# RP2350 register map
Vendor: Raspberry Pi; Series: RP; File version: 0.1
CPU: CM33 r1p0, little endian, MPU, FPU, DSP, VTOR, 4 interrupt priority bits, 52 interrupts, 8 SAU regions
Registers are 32-bit, read-write, reset 0x0 unless marked. A register's access mark holds for its fields unless they carry their own. Offsets are from the block's base; [hi:lo] are bit positions.

## HSTX_FIFO — FIFO status and write access for HSTX
Base 0x50600000
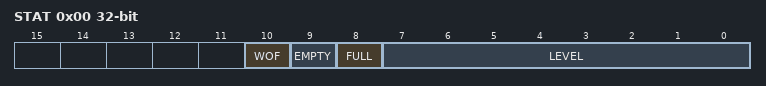
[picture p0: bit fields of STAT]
0x00 STAT — FIFO status
  [10] WOF write-1-clears — FIFO was written when full. Write 1 to clear.
  [9] EMPTY ro — Pre-defined description
  [8] FULL ro — Pre-defined description
  [7:0] LEVEL ro — Pre-defined description
0x04 FIFO — Write access to FIFO
  [31:0] FIFO wo — Pre-defined description

## EPPB — Cortex-M33 EPPB vendor register block for RP2350
Base 0xE0080000
0x00 NMI_MASK0 — NMI mask for IRQs 0 through 31. This register is core-local, and is reset by a processor warm reset.
  [31:0] NMI_MASK0 — Pre-defined description
0x04 NMI_MASK1 — NMI mask for IRQs 0 though 51. This register is core-local, and is reset by a processor warm reset.
  [19:0] NMI_MASK1 — Pre-defined description
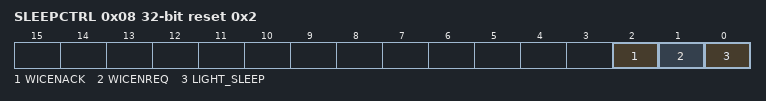
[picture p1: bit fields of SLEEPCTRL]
0x08 SLEEPCTRL reset 0x2 — Nonstandard sleep control register
  [2] WICENACK ro — Status signal from the processor's interrupt controller. Changes to WICENREQ are eventually reflected in WICENACK.
  [1] WICENREQ — Request that the next processor deep sleep is a WIC sleep. After setting this bit, before sleeping, poll WICENACK to ensure the processor interrupt controller has acknowledged the change.
  [0] LIGHT_SLEEP — By default, any processor sleep will deassert the system-level clock request. Reenabling the clocks incurs 5 cycles of additional latency on wakeup. Setting LIGHT_SLEEP to 1 keeps the clock request asserted during a normal sleep (Arm SCR.SLEEPDEEP = 0), for faster wakeup. Processor deep sleep (Arm SCR.SLEEPDEEP = 1) is not affected, and will always deassert the system-level clock request.

## XIP_AUX — Auxiliary DMA access to XIP FIFOs, via fast AHB bus access
Base 0x50500000
0x00 STREAM — Read the XIP stream FIFO (fast bus access to XIP_CTRL_STREAM_FIFO)
  [31:0] STREAM ro read-modifies — Pre-defined description
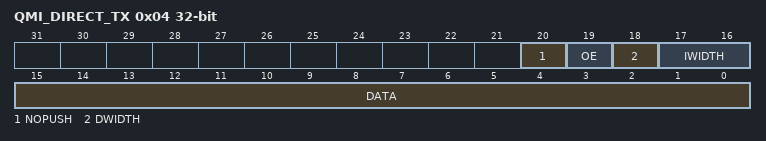
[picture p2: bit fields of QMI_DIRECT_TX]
0x04 QMI_DIRECT_TX — Write to the QMI direct-mode TX FIFO (fast bus access to QMI_DIRECT_TX)
  [20] NOPUSH wo — Inhibit the RX FIFO push that would correspond to this TX FIFO entry. Useful to avoid garbage appearing in the RX FIFO when pushing the command at the beginning of a SPI transfer.
  [19] OE wo — Output enable (active-high). For single width (SPI), this field is ignored, and SD0 is always set to output, with SD1 always set to input. For dual and quad width (DSPI/QSPI), this sets whether the relevant SDx pads are set to output whilst transferring this FIFO record. In this case the command/address should have OE set, and the data transfer should have OE set or clear depending on the direction of the transfer.
  [18] DWIDTH wo — Data width. If 0, hardware will transmit the 8 LSBs of the DIRECT_TX DATA field, and return an 8-bit value in the 8 LSBs of DIRECT_RX. If 1, the full 16-bit width is used. 8-bit and 16-bit transfers can be mixed freely.
  [17:16] IWIDTH wo — Configure whether this FIFO record is transferred with single/dual/quad interface width (0/1/2). Different widths can be mixed freely.
    0=S (Single width); 1=D (Dual width); 2=Q (Quad width)
  [15:0] DATA wo — Data pushed here will be clocked out falling edges of SCK (or before the very first rising edge of SCK, if this is the first pulse). For each byte clocked out, the interface will simultaneously sample one byte, on rising edges of SCK, and push this to the DIRECT_RX FIFO. For 16-bit data, the least-significant byte is transmitted first.
0x08 QMI_DIRECT_RX — Read from the QMI direct-mode RX FIFO (fast bus access to QMI_DIRECT_RX)
  [15:0] QMI_DIRECT_RX ro read-modifies — With each byte clocked out on the serial interface, one byte will simultaneously be clocked in, and will appear in this FIFO. The serial interface will stall when this FIFO is full, to avoid dropping data. When 16-bit data is pushed into the TX FIFO, the corresponding RX FIFO push will also contain 16 bits of data. The least-significant byte is the first one received.
